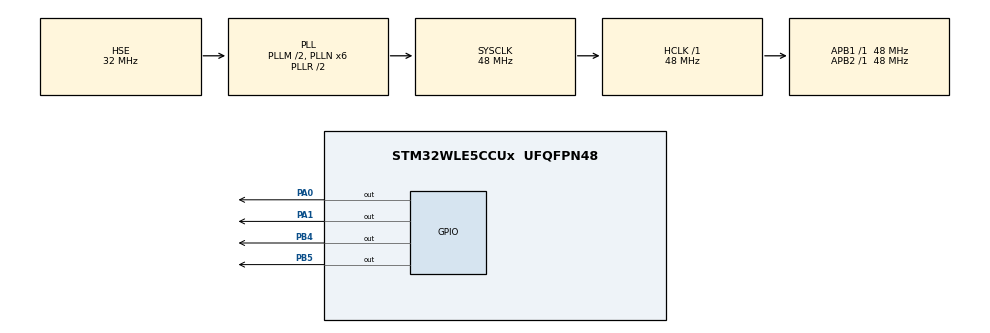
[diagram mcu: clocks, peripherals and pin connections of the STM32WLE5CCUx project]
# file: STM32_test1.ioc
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Mcu.Family=STM32WL
Mcu.Name=STM32WLE5CCUx
Mcu.Package=UFQFPN48
NVIC.PriorityGroup=NVIC_PRIORITYGROUP_4
OSC_IN.Mode=HSE-External-Oscillator
OSC_IN.Signal=RCC_OSC_IN
OSC_OUT.Mode=HSE-External-Oscillator
OSC_OUT.Signal=RCC_OSC_OUT
PA0.Signal=GPIO_Output
PA1.Signal=GPIO_Output
PA13.Mode=Serial_Wire
PA13.Signal=DEBUG_JTMS-SWDIO
PA14.Mode=Serial_Wire
PA14.Signal=DEBUG_JTCK-SWCLK
PB4.Signal=GPIO_Output
PB5.Signal=GPIO_Output
ProjectManager.HeapSize=0x200
ProjectManager.StackSize=0x400
ProjectManager.TargetToolchain=STM32CubeIDE
RCC.AHBFreq_Value=48000000
RCC.APB1Freq_Value=48000000
RCC.APB1TimFreq_Value=48000000
RCC.APB2Freq_Value=48000000
RCC.APB2TimFreq_Value=48000000
RCC.APB3Freq_Value=48000000
RCC.CortexFreq_Value=48000000
RCC.HCLKFreq_Value=48000000
RCC.HSE_Timout=10000
RCC.HSE_VALUE=32000000
RCC.HSI_VALUE=16000000
RCC.LSE_VALUE=32768
RCC.PLLM=RCC_PLLM_DIV2
RCC.PLLN=6
RCC.PLLSourceVirtual=RCC_PLLSOURCE_HSE
RCC.SYSCLKFreq_VALUE=48000000
RCC.SYSCLKSource=RCC_SYSCLKSOURCE_PLLCLK
RCC.VCOOutputFreq_Value=96000000
VP_RTC_VS_RTC_Activate.Mode=RTC_Enabled
VP_RTC_VS_RTC_Calendar.Mode=RTC_Calendar
board=custom

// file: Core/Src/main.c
/* USER CODE BEGIN Header */
/**
  ******************************************************************************
  * @file           : main.c
  * @brief          : Main program body
  ******************************************************************************
  * @attention
  *
  * Copyright (c) 2026 STMicroelectronics.
  * All rights reserved.
  *
  * This software is licensed under terms that can be found in the LICENSE file
  * in the root directory of this software component.
  * If no LICENSE file comes with this software, it is provided AS-IS.
  *
  ******************************************************************************
  */
/* USER CODE END Header */
#include "main.h"
#include "rtc.h"
#include "gpio.h"

void SystemClock_Config(void);

int main(void)
{

  /* MCU Configuration--------------------------------------------------------*/

  /* Reset of all peripherals, Initializes the Flash interface and the Systick. */
  HAL_Init();

  /* Configure the system clock */
  SystemClock_Config();

  /* Initialize all configured peripherals */
  MX_GPIO_Init();
  MX_RTC_Init();

  /* Infinite loop */
  while (1)
  {

    /* USER CODE BEGIN 3 */
	  HAL_GPIO_TogglePin(GPIOB, GPIO_PIN_4);
    HAL_GPIO_TogglePin(GPIOB, GPIO_PIN_5);
    HAL_GPIO_TogglePin(GPIOA, GPIO_PIN_0);
    HAL_GPIO_TogglePin(GPIOA, GPIO_PIN_1);
	  HAL_Delay(500);
  }
  /* USER CODE END 3 */
}

void SystemClock_Config(void)
{
  RCC_OscInitTypeDef RCC_OscInitStruct = {0};
  RCC_ClkInitTypeDef RCC_ClkInitStruct = {0};

  /** Configure the main internal regulator output voltage
  */
  __HAL_PWR_VOLTAGESCALING_CONFIG(PWR_REGULATOR_VOLTAGE_SCALE1);

  /** Initializes the CPU, AHB and APB buses clocks
  */
  RCC_OscInitStruct.OscillatorType = RCC_OSCILLATORTYPE_LSI|RCC_OSCILLATORTYPE_HSE;
  RCC_OscInitStruct.HSEState = RCC_HSE_ON;
  RCC_OscInitStruct.LSIDiv = RCC_LSI_DIV1;
  RCC_OscInitStruct.HSEDiv = RCC_HSE_DIV1;
  RCC_OscInitStruct.LSIState = RCC_LSI_ON;
  RCC_OscInitStruct.PLL.PLLState = RCC_PLL_ON;
  RCC_OscInitStruct.PLL.PLLSource = RCC_PLLSOURCE_HSE;
  RCC_OscInitStruct.PLL.PLLM = RCC_PLLM_DIV2;
  RCC_OscInitStruct.PLL.PLLN = 6;
  RCC_OscInitStruct.PLL.PLLP = RCC_PLLP_DIV2;
  RCC_OscInitStruct.PLL.PLLR = RCC_PLLR_DIV2;
  RCC_OscInitStruct.PLL.PLLQ = RCC_PLLQ_DIV2;
  if (HAL_RCC_OscConfig(&RCC_OscInitStruct) != HAL_OK)
  {
    Error_Handler();
  }

  /** Configure the SYSCLKSource, HCLK, PCLK1 and PCLK2 clocks dividers
  */
  RCC_ClkInitStruct.ClockType = RCC_CLOCKTYPE_HCLK3|RCC_CLOCKTYPE_HCLK
                              |RCC_CLOCKTYPE_SYSCLK|RCC_CLOCKTYPE_PCLK1
                              |RCC_CLOCKTYPE_PCLK2;
  RCC_ClkInitStruct.SYSCLKSource = RCC_SYSCLKSOURCE_PLLCLK;
  RCC_ClkInitStruct.AHBCLKDivider = RCC_SYSCLK_DIV1;
  RCC_ClkInitStruct.APB1CLKDivider = RCC_HCLK_DIV1;
  RCC_ClkInitStruct.APB2CLKDivider = RCC_HCLK_DIV1;
  RCC_ClkInitStruct.AHBCLK3Divider = RCC_SYSCLK_DIV1;

  if (HAL_RCC_ClockConfig(&RCC_ClkInitStruct, FLASH_LATENCY_2) != HAL_OK)
  {
    Error_Handler();
  }
}

void Error_Handler(void)
{
  __disable_irq();
  while (1)
  {
  }
}
